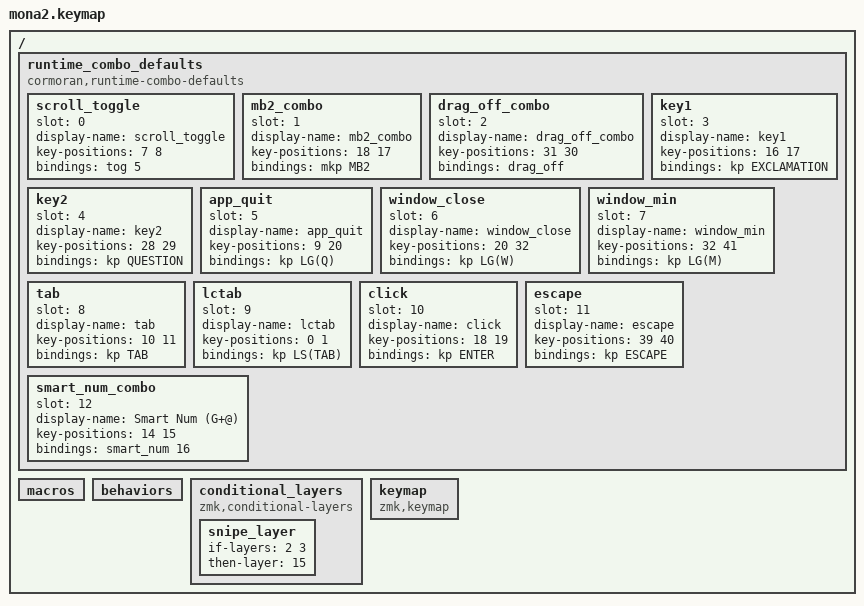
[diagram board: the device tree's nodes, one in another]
#include <input/processors.dtsi>
#include <dt-bindings/zmk/input_transform.h>
#include <zephyr/dt-bindings/input/input-event-codes.h>
#include <behaviors/runtime-sensor-rotate.dtsi>
#include <behaviors.dtsi>
/* DYA Studio から作成したマクロを呼び出す `&rmacro <slot>` を定義する。
   slot は 0 〜 CONFIG_ZMK_RUNTIME_MACRO_COUNT-1 (現状 0〜7)。
   どのマクロがどのスロットに入っているかは DYA Studio のマクロ一覧で確認する。
   キーへの割り当ては DYA Studio のキーマップエディタからも行える。 */
#include <behaviors/runtime_macro.dtsi>
/* デフォルトレイヤー変更 behavior `&df`。
   DYA Studio の「OSごとのデフォルトレイヤー」から設定できるほか、
   キーマップエディタで `&df DF_SEL <layer>` / `&df DF_INC` を
   任意のキーに割り当てられる。 */
#include <behaviors/default_layer.dtsi>
#include <dt-bindings/zmk_behavior_default_layer/default_layer.h>
#include <dt-bindings/zmk/bt.h>
#include <dt-bindings/zmk/keys.h>
#include <dt-bindings/zmk/outputs.h>
#include <dt-bindings/zmk/pointing.h>

/* ZMK 側で 10 が定義済みなので警告回避のため一旦 undef */




/* 〈Release Recollection〉— moNa2(DYA Studio) 版エントリ。
 * レイヤー・マクロ・behavior・ジェスチャは Cardinal 版 config/keymap/ を流用。
 * コンボのみ DYA Studio から編集できる runtime_combo_defaults へ移行（12件）。 */
#include "keymap/00_prelude.dtsi"

/ {
    runtime_combo_defaults {
        compatible = "cormoran,runtime-combo-defaults";

        scroll_toggle {
            slot = <0>;
            display-name = "scroll_toggle";
            key-positions = <7 8>;
            bindings = <&tog 5>;
        };

        mb2_combo {
            slot = <1>;
            display-name = "mb2_combo";
            key-positions = <18 17>;
            bindings = <&mkp MB2>;
        };

        drag_off_combo {
            slot = <2>;
            display-name = "drag_off_combo";
            key-positions = <31 30>;
            bindings = <&drag_off>;
        };

        key1 {
            slot = <3>;
            display-name = "key1";
            key-positions = <16 17>;
            bindings = <&kp EXCLAMATION>;
        };

        key2 {
            slot = <4>;
            display-name = "key2";
            key-positions = <28 29>;
            bindings = <&kp QUESTION>;
        };

        app_quit {
            slot = <5>;
            display-name = "app_quit";
            key-positions = <9 20>;
            bindings = <&kp LG(Q)>;
        };

        window_close {
            slot = <6>;
            display-name = "window_close";
            key-positions = <20 32>;
            bindings = <&kp LG(W)>;
        };

        window_min {
            slot = <7>;
            display-name = "window_min";
            key-positions = <32 41>;
            bindings = <&kp LG(M)>;
        };

        tab {
            slot = <8>;
            display-name = "tab";
            key-positions = <10 11>;
            bindings = <&kp TAB>;
        };

        lctab {
            slot = <9>;
            display-name = "lctab";
            key-positions = <0 1>;
            bindings = <&kp LS(TAB)>;
        };

        click {
            slot = <10>;
            display-name = "click";
            key-positions = <18 19>;
            bindings = <&kp ENTER>;
        };

        escape {
            slot = <11>;
            display-name = "escape";
            key-positions = <39 40>;
            bindings = <&kp ESCAPE>;
        };

        smart_num_combo {
            slot = <12>;
            display-name = "Smart Num (G+@)";
            key-positions = <14 15>;
            bindings = <&smart_num 16>;
        };
    };

    macros {
        #include "keymap/20_macros.dtsi"
    };

    behaviors {
        #include "keymap/30_enhance_armament_base.dtsi"
        #include "keymap/31_enhance_armament_layers.dtsi"
        #include "keymap/35_enhance_armament.dtsi"
        #include "keymap/40_sharp_nail.dtsi"
        #include "keymap/41_vorpal_strike.dtsi"
        #include "keymap/42_the_eclipse.dtsi"
        #include "keymap/43_howling_octave.dtsi"
        #include "keymap/44_sonic_leap.dtsi"
        #include "keymap/45_vertical_square.dtsi"
        #include "keymap/46_starburst_stream.dtsi"
        #include "keymap/47_horizontal.dtsi"
    };

    conditional_layers {
        compatible = "zmk,conditional-layers";
        snipe_layer {
            if-layers = <2 3>;
            then-layer = <15>;
        };
    };

    keymap {
        compatible = "zmk,keymap";

        #include "keymap/layers/00_default.dtsi"
        #include "keymap/layers/01_function.dtsi"
        #include "keymap/layers/02_sign.dtsi"
        #include "keymap/layers/03_num.dtsi"
        #include "keymap/layers/04_mouse.dtsi"
        #include "keymap/layers/05_scroll.dtsi"
        #include "keymap/layers/06_bluetooth.dtsi"
        #include "keymap/layers/07_gesture_e.dtsi"
        #include "keymap/layers/08_gesture_r.dtsi"
        #include "keymap/layers/09_gesture_s.dtsi"
        #include "keymap/layers/10_gesture_b.dtsi"
        #include "keymap/layers/11_gesture_t.dtsi"
        #include "keymap/layers/12_gesture_a.dtsi"
        #include "keymap/layers/13_gesture_d.dtsi"
        #include "keymap/layers/14_gesture_w.dtsi"
        #include "keymap/layers/15_snipe.dtsi"
        #include "keymap/layers/16_num_smart.dtsi"
    };
};
